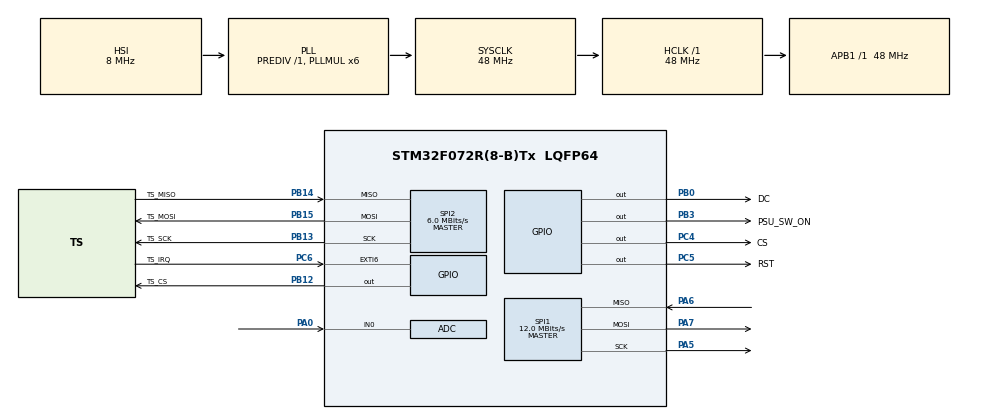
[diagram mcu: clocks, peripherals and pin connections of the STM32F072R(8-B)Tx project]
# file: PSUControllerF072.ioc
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ADC.ClockPrescaler=ADC_CLOCK_SYNC_PCLK_DIV4
ADC.ContinuousConvMode=ENABLE
ADC.DMAContinuousRequests=DISABLE
ADC.SamplingTime=ADC_SAMPLETIME_1CYCLE_5
Mcu.Family=STM32F0
Mcu.Name=STM32F072R(8-B)Tx
Mcu.Package=LQFP64
NVIC.EXTI4_15_IRQn=true\:0\:0\:false\:false\:true\:true\:true
NVIC.TIM17_IRQn=true\:0\:0\:false\:false\:true\:true\:true
PA0.Mode=IN0
PA0.Signal=ADC_IN0
PA13.Mode=Serial_Wire
PA13.Signal=SYS_SWDIO
PA14.Mode=Serial_Wire
PA14.Signal=SYS_SWCLK
PA5.Mode=Full_Duplex_Master
PA5.Signal=SPI1_SCK
PA6.Mode=Full_Duplex_Master
PA6.Signal=SPI1_MISO
PA7.Mode=Full_Duplex_Master
PA7.Signal=SPI1_MOSI
PB0.GPIO_Label=DC
PB0.GPIO_Speed=GPIO_SPEED_FREQ_HIGH
PB0.Signal=GPIO_Output
PB12.GPIO_Label=TS_CS
PB12.GPIO_Speed=GPIO_SPEED_FREQ_HIGH
PB12.Signal=GPIO_Output
PB13.GPIO_Label=TS_SCK
PB13.Mode=Full_Duplex_Master
PB13.Signal=SPI2_SCK
PB14.GPIO_Label=TS_MISO
PB14.Mode=Full_Duplex_Master
PB14.Signal=SPI2_MISO
PB15.GPIO_Label=TS_MOSI
PB15.Mode=Full_Duplex_Master
PB15.Signal=SPI2_MOSI
PB3.GPIO_Label=PSU_SW_ON
PB3.GPIO_PuPd=GPIO_PULLDOWN
PB3.GPIO_Speed=GPIO_SPEED_FREQ_LOW
PB3.Signal=GPIO_Output
PC4.GPIO_Label=CS
PC4.GPIO_Speed=GPIO_SPEED_FREQ_HIGH
PC4.Signal=GPIO_Output
PC5.GPIO_Label=RST
PC5.GPIO_Speed=GPIO_SPEED_FREQ_HIGH
PC5.Signal=GPIO_Output
PC6.GPIO_Label=TS_IRQ
PC6.GPIO_ModeDefaultEXTI=GPIO_MODE_IT_FALLING
PC6.GPIO_PuPd=GPIO_PULLUP
PC6.Signal=GPXTI6
ProjectManager.HeapSize=0x200
ProjectManager.StackSize=0x400
ProjectManager.TargetToolchain=STM32CubeIDE
RCC.AHBFreq_Value=48000000
RCC.APB1Freq_Value=48000000
RCC.APB1TimFreq_Value=48000000
RCC.HCLKFreq_Value=48000000
RCC.PLLMUL=RCC_PLL_MUL6
RCC.SYSCLKFreq_VALUE=48000000
RCC.SYSCLKSource=RCC_SYSCLKSOURCE_PLLCLK
SPI1.BaudRatePrescaler=SPI_BAUDRATEPRESCALER_4
SPI1.CalculateBaudRate=12.0 MBits/s
SPI1.DataSize=SPI_DATASIZE_8BIT
SPI1.Direction=SPI_DIRECTION_2LINES
SPI1.Mode=SPI_MODE_MASTER
SPI1.NSSPMode=SPI_NSS_PULSE_DISABLE
SPI1.VirtualType=VM_MASTER
SPI2.BaudRatePrescaler=SPI_BAUDRATEPRESCALER_8
SPI2.CalculateBaudRate=6.0 MBits/s
SPI2.DataSize=SPI_DATASIZE_8BIT
SPI2.Direction=SPI_DIRECTION_2LINES
SPI2.Mode=SPI_MODE_MASTER
SPI2.NSSPMode=SPI_NSS_PULSE_DISABLE
SPI2.VirtualType=VM_MASTER
TIM17.Period=1024
VP_TIM17_VS_ClockSourceINT.Mode=Enable_Timer
board=custom

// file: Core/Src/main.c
/* USER CODE BEGIN Header */
/**
  ******************************************************************************
  * @file           : main.c
  * @brief          : Main program body
  ******************************************************************************
  * @attention
  *
  * <h2><center>&copy; Copyright (c) 2020 STMicroelectronics.
  * All rights reserved.</center></h2>
  *
  * This software component is licensed by ST under BSD 3-Clause license,
  * the "License"; You may not use this file except in compliance with the
  * License. You may obtain a copy of the License at:
  *                        opensource.org/licenses/BSD-3-Clause
  *
  ******************************************************************************
  */
/* USER CODE END Header */

#include "main.h"
#include "adc.h"
#include "spi.h"
#include "tim.h"
#include "gpio.h"

/* USER CODE BEGIN Includes */
#include "ILI9341_STM32_Driver.h"
#include "ILI9341_GFX.h"
#include "TSC2046_STM32.h"

#include "UserTasks.h"

#include <stdio.h>
/* USER CODE END Includes */

void SystemClock_Config(void);

int main(void)
{

  /* MCU Configuration--------------------------------------------------------*/

  /* Reset of all peripherals, Initializes the Flash interface and the Systick. */
  HAL_Init();

  /* Configure the system clock */
  SystemClock_Config();

  /* Initialize all configured peripherals */
  MX_GPIO_Init();
  MX_SPI1_Init();
  MX_SPI2_Init();
  MX_ADC_Init();
  MX_TIM17_Init();
  /* USER CODE BEGIN 2 */
  // init ILI9341 library
  ILI9341_Init();
  ILI9341_Set_Rotation(SCREEN_HORIZONTAL_1);
  ILI9341_Fill_Screen(LBLUE);

  // init TSC2046 library
  TSC2046_HM_Init();

  // init ADC
  HAL_ADCEx_Calibration_Start(&hadc);
  HAL_ADC_Start(&hadc);

  /* USER CODE END 2 */

  /* Infinite loop */
  /* USER CODE BEGIN WHILE */
  while (1)
  {
	  UserDisplayTask();
	  UserAdcTask();
    /* USER CODE END WHILE */

  }
}

void SystemClock_Config(void)
{
  RCC_OscInitTypeDef RCC_OscInitStruct = {0};
  RCC_ClkInitTypeDef RCC_ClkInitStruct = {0};

  /** Initializes the CPU, AHB and APB busses clocks
  */
  RCC_OscInitStruct.OscillatorType = RCC_OSCILLATORTYPE_HSI;
  RCC_OscInitStruct.HSIState = RCC_HSI_ON;
  RCC_OscInitStruct.HSICalibrationValue = RCC_HSICALIBRATION_DEFAULT;
  RCC_OscInitStruct.PLL.PLLState = RCC_PLL_ON;
  RCC_OscInitStruct.PLL.PLLSource = RCC_PLLSOURCE_HSI;
  RCC_OscInitStruct.PLL.PLLMUL = RCC_PLL_MUL6;
  RCC_OscInitStruct.PLL.PREDIV = RCC_PREDIV_DIV1;
  if (HAL_RCC_OscConfig(&RCC_OscInitStruct) != HAL_OK)
  {
    Error_Handler();
  }
  /** Initializes the CPU, AHB and APB busses clocks
  */
  RCC_ClkInitStruct.ClockType = RCC_CLOCKTYPE_HCLK|RCC_CLOCKTYPE_SYSCLK
                              |RCC_CLOCKTYPE_PCLK1;
  RCC_ClkInitStruct.SYSCLKSource = RCC_SYSCLKSOURCE_PLLCLK;
  RCC_ClkInitStruct.AHBCLKDivider = RCC_SYSCLK_DIV1;
  RCC_ClkInitStruct.APB1CLKDivider = RCC_HCLK_DIV1;

  if (HAL_RCC_ClockConfig(&RCC_ClkInitStruct, FLASH_LATENCY_1) != HAL_OK)
  {
    Error_Handler();
  }
}

void Error_Handler(void)
{
}

/************************ (C) COPYRIGHT STMicroelectronics *****END OF FILE****/
